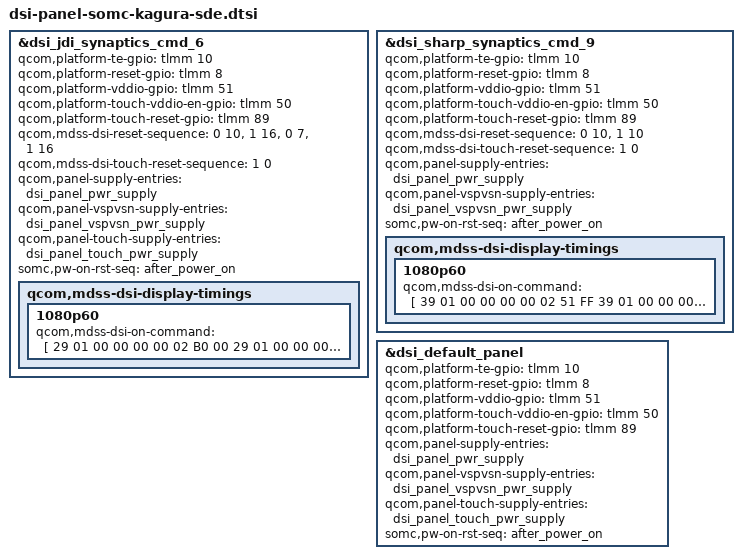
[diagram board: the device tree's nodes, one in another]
/* Copyright (c) 2018, AngeloGioacchino Del Regno <kholk11@gmail.com>
 *
 * This program is free software; you can redistribute it and/or modify
 * it under the terms of the GNU General Public License version 2 and
 * only version 2 as published by the Free Software Foundation.
 *
 * This program is distributed in the hope that it will be useful,
 * but WITHOUT ANY WARRANTY; without even the implied warranty of
 * MERCHANTABILITY or FITNESS FOR A PARTICULAR PURPOSE.  See the
 * GNU General Public License for more details.
 */

&dsi_jdi_synaptics_cmd_6 {
		qcom,platform-te-gpio = <&tlmm 10 0>;
		qcom,platform-reset-gpio = <&tlmm 8 0>;
		qcom,platform-vddio-gpio = <&tlmm 51 0>;
		qcom,platform-touch-vddio-en-gpio = <&tlmm 50 0>;
		qcom,platform-touch-reset-gpio = <&tlmm 89 0>;
		qcom,mdss-dsi-reset-sequence = <0 10>, <1 16>, <0 7>, <1 16>;
		qcom,mdss-dsi-touch-reset-sequence = <1 0>;
		qcom,panel-supply-entries = <&dsi_panel_pwr_supply>;
		qcom,panel-vspvsn-supply-entries = <&dsi_panel_vspvsn_pwr_supply>;
		qcom,panel-touch-supply-entries = <&dsi_panel_touch_pwr_supply>;
		somc,pw-on-rst-seq = "after_power_on";
		qcom,mdss-dsi-display-timings {
			1080p60 {
				qcom,mdss-dsi-on-command = [
						29 01 00 00 00 00 02 B0 00
						29 01 00 00 00 00 02 D6 01
						29 01 00 00 00 00 03 C4 70 03
						29 01 00 00 00 00 1B ED 27 31 2F 13 00 6A 99 03 17 91 F2 00 00 03 14 17 3F 14 12 26 23 00 20 00 00 57
						29 01 00 00 00 00 1B EE 13 61 5F 09 00 6A 99 03 00 01 B2 00 00 03 00 00 33 14 12 00 21 00 20 00 00 57
						29 01 00 00 00 00 1B EF 27 31 2F 13 00 00 00 00 00 00 00 00 00 03 14 17 0F 14 00 00 20 00 00 00 00 A6
						29 01 00 00 00 00 1B F0 E3 07 73 DF 00 00 00 00 00 00 00 00 E0 E3 00 00 03 14 00 00 20 00 00 00 00 A7
						39 01 00 00 00 00 02 35 00
						39 01 00 00 00 00 02 36 00
						39 01 00 00 00 00 02 3A 77
						39 01 00 00 00 00 05 2A 00 00 04 37
						39 01 00 00 00 00 05 2B 00 00 07 7F
						39 01 00 00 00 00 03 44 00 00
						39 01 00 00 78 00 01 11
						39 01 00 00 00 00 01 29];
			};
		};
};

&dsi_sharp_synaptics_cmd_9 {
		qcom,platform-te-gpio = <&tlmm 10 0>;
		qcom,platform-reset-gpio = <&tlmm 8 0>;
		qcom,platform-vddio-gpio = <&tlmm 51 0>;
		qcom,platform-touch-vddio-en-gpio = <&tlmm 50 0>;
		qcom,platform-touch-reset-gpio = <&tlmm 89 0>;
		qcom,mdss-dsi-reset-sequence = <0 10>, <1 10>;
		qcom,mdss-dsi-touch-reset-sequence = <1 0>;
		qcom,panel-supply-entries = <&dsi_panel_pwr_supply>;
		qcom,panel-vspvsn-supply-entries = <&dsi_panel_vspvsn_pwr_supply>;
		somc,pw-on-rst-seq = "after_power_on";
		qcom,mdss-dsi-display-timings {
			1080p60 {
				qcom,mdss-dsi-on-command = [
						39 01 00 00 00 00 02 51 FF
						39 01 00 00 00 00 02 53 0C
						39 01 00 00 00 00 02 55 00
						39 01 00 00 00 00 02 35 00
						23 01 00 00 00 00 02 B0 04
						23 01 00 00 00 00 02 D6 01
						29 01 00 00 00 00 09 C9 1F 60 1F 60 90 90 C4 00
						29 01 00 00 00 00 0C D5 66 00 00 01 25 01 25 00 25 00 25
						29 01 00 00 00 00 11 D0 19 01 91 0B 94 0F 0A 00 00 00 19 99 00 00 00 00
						29 01 00 00 00 00 1D D3 1B 3B BB BD B5 33 33 33 00 80 A6 A0 5F 5F 33 33 33 F7 F2 0F 7D 7C FF 0F 99 00 FF FF
						29 01 00 00 00 00 21 D7 04 FF 23 55 47 1E FE 78 F0 19 A8 0F 38 3E 60 1C 0F 8F C7 E3 99 E1 20 00 00 00 00 F0 EB 39 18 07
						29 01 00 00 00 00 20 C1 84 00 00 00 88 01 00 40 C0 35 E6 1A 63 CD B1 E6 C0 7A 00 C8 08 00 00 AA 40 02 82 01 08 00 01
						29 01 00 00 00 00 1F C7 06 10 1A 23 35 44 4E 5D 42 4B 57 64 6B 71 79 04 0E 19 22 35 43 4E 5D 42 4A 55 63 6B 70 79
						29 01 00 00 00 00 14 C8 01 00 FD 01 FF FC 00 00 FD 01 FF FC 00 00 FD 01 FF FC 00
						05 01 00 00 00 00 01 29
						05 01 00 00 78 00 01 11];
			};
		};
};

&dsi_default_panel {
		qcom,platform-te-gpio = <&tlmm 10 0>;
		qcom,platform-reset-gpio = <&tlmm 8 0>;
		qcom,platform-vddio-gpio = <&tlmm 51 0>;
		qcom,platform-touch-vddio-en-gpio = <&tlmm 50 0>;
		qcom,platform-touch-reset-gpio = <&tlmm 89 0>;
		qcom,panel-supply-entries = <&dsi_panel_pwr_supply>;
		qcom,panel-vspvsn-supply-entries = <&dsi_panel_vspvsn_pwr_supply>;
		qcom,panel-touch-supply-entries = <&dsi_panel_touch_pwr_supply>;
		somc,pw-on-rst-seq = "after_power_on";
};
